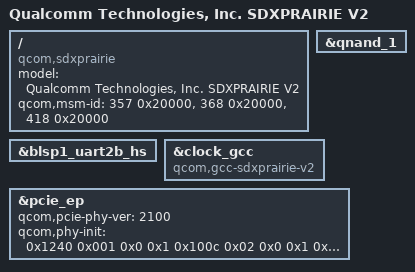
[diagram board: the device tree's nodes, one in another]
/* Copyright (c) 2019, The Linux Foundation. All rights reserved.
 *
 * This program is free software; you can redistribute it and/or modify
 * it under the terms of the GNU General Public License version 2 and
 * only version 2 as published by the Free Software Foundation.
 *
 * This program is distributed in the hope that it will be useful,
 * but WITHOUT ANY WARRANTY; without even the implied warranty of
 * MERCHANTABILITY or FITNESS FOR A PARTICULAR PURPOSE.  See the
 * GNU General Public License for more details.
 */

#include "sdxprairie.dtsi"

/ {
	model = "Qualcomm Technologies, Inc. SDXPRAIRIE V2";
	compatible = "qcom,sdxprairie";
	qcom,msm-id = <357 0x20000>, <368 0x20000>, <418 0x20000>;
};

&qnand_1 {
	status = "ok";
};

&blsp1_uart2b_hs {
	status = "okay";
};

&clock_gcc {
	compatible = "qcom,gcc-sdxprairie-v2", "syscon";
};

&pcie_ep {
	qcom,pcie-phy-ver = <2100>;
	qcom,phy-init = <0x1240 0x001 0x0 0x1
			0x100c 0x02 0x0 0x1
			0x1044 0x18 0x0 0x1
			0x104c 0x07 0x0 0x1
			0x1058 0x0f 0x0 0x1
			0x1074 0x09 0x0 0x1
			0x1078 0x0a 0x0 0x1
			0x107c 0x18 0x0 0x1
			0x1080 0x19 0x0 0x1
			0x1084 0x06 0x0 0x1
			0x1088 0x03 0x0 0x1
			0x1094 0x00 0x0 0x1
			0x10a4 0x46 0x0 0x1
			0x10a8 0x04 0x0 0x1
			0x10ac 0x7f 0x0 0x1
			0x10b0 0x02 0x0 0x1
			0x10b4 0xff 0x0 0x1
			0x10b8 0x04 0x0 0x1
			0x10bc 0x25 0x0 0x1
			0x10c4 0x28 0x0 0x1
			0x10d4 0x08 0x0 0x1
			0x10f4 0xfb 0x0 0x1
			0x10f8 0x01 0x0 0x1
			0x110c 0x02 0x0 0x1
			0x1158 0x12 0x0 0x1
			0x115c 0x00 0x0 0x1
			0x1168 0x05 0x0 0x1
			0x116c 0x04 0x0 0x1
			0x119c 0x88 0x0 0x1
			0x11a0 0x03 0x0 0x1
			0x11ac 0x56 0x0 0x1
			0x11b0 0x1d 0x0 0x1
			0x11b4 0x4b 0x0 0x1
			0x11b8 0x1f 0x0 0x1
			0x11bc 0x22 0x0 0x1
			0x11a4 0x17 0x0 0x1
			0x11a8 0x0b 0x0 0x1
			0x0088 0x05 0x0 0x1
			0x008c 0xf6 0x0 0x1
			0x0090 0x13 0x0 0x1
			0x00e0 0x00 0x0 0x1
			0x00c4 0x00 0x0 0x1
			0x0208 0x0c 0x0 0x1
			0x0258 0x16 0x0 0x1
			0x0378 0x44 0x0 0x1
			0x03c8 0x1a 0x0 0x1
			0x03cc 0x5a 0x0 0x1
			0x03d0 0x09 0x0 0x1
			0x03d4 0x37 0x0 0x1
			0x03d8 0xbd 0x0 0x1
			0x03dc 0xf9 0x0 0x1
			0x03e0 0xbf 0x0 0x1
			0x03e4 0xce 0x0 0x1
			0x03e8 0x62 0x0 0x1
			0x03ec 0xbf 0x0 0x1
			0x03f0 0x7d 0x0 0x1
			0x03f4 0xbf 0x0 0x1
			0x03f8 0xcf 0x0 0x1
			0x03fc 0xd6 0x0 0x1
			0x02ac 0x7f 0x0 0x1
			0x0310 0x55 0x0 0x1
			0x0334 0x0c 0x0 0x1
			0x0338 0x00 0x0 0x1
			0x0350 0x08 0x0 0x1
			0x0400 0xa0 0x0 0x1
			0x043c 0x02 0x0 0x1
			0x0888 0x05 0x0 0x1
			0x088c 0xf6 0x0 0x1
			0x0890 0x13 0x0 0x1
			0x08e0 0x00 0x0 0x1
			0x08c4 0x00 0x0 0x1
			0x0a08 0x0c 0x0 0x1
			0x0a58 0x16 0x0 0x1
			0x0b78 0x44 0x0 0x1
			0x0bc8 0x1a 0x0 0x1
			0x0bcc 0x5a 0x0 0x1
			0x0bd0 0x09 0x0 0x1
			0x0bd4 0x37 0x0 0x1
			0x0bd8 0xbd 0x0 0x1
			0x0bdc 0xf9 0x0 0x1
			0x0be0 0xbf 0x0 0x1
			0x0be4 0xce 0x0 0x1
			0x0be8 0x62 0x0 0x1
			0x0bec 0xbf 0x0 0x1
			0x0bf0 0x7d 0x0 0x1
			0x0bf4 0xbf 0x0 0x1
			0x0bf8 0xcf 0x0 0x1
			0x0bfc 0xd6 0x0 0x1
			0x0aac 0x7f 0x0 0x1
			0x0b10 0x55 0x0 0x1
			0x0b34 0x0c 0x0 0x1
			0x0b38 0x00 0x0 0x1
			0x0b50 0x08 0x0 0x1
			0x0c00 0xa0 0x0 0x1
			0x0c3c 0x02 0x0 0x1
			0x13e0 0x16 0x0 0x1
			0x13e4 0x02 0x0 0x1
			0x1708 0x02 0x0 0x1
			0x16a0 0x17 0x0 0x1
			0x13d8 0x01 0x0 0x1
			0x16fc 0x01 0x0 0x1
			0x16f0 0x13 0x0 0x1
			0x16f4 0x13 0x0 0x1
			0x1e24 0x00 0x0 0x1
			0x1e28 0x00 0x0 0x1
			0x1200 0x000 0x0 0x1
			0x1244 0x003 0x0 0x1>;
};
